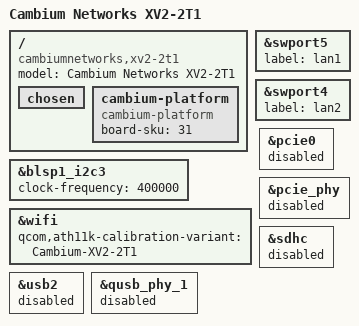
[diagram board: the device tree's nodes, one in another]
// SPDX-License-Identifier: (GPL-2.0+)

/*
 * First, RAM-only XV2-2T1 trial. The existing XE3-4 port supplies the
 * IPQ6018 Ethernet/flash baseline; the 7.2-r1 OEM XV2-2T1 tree supplies
 * the board identity and the corrected SPI-NOR partition layout.
 *
 * No persistent storage, boot environment, or PoE output is enabled for
 * writing/operation by this recovery tree. The integrated radio is enabled
 * only for the physically checked XV2-2T1 variant in the radio trial.
 */

#include "ipq6010-xe3-4.dts"
#include "ipq6010-jaguar-storage-recovery.dtsi"
#include "ipq6010-jaguar-controls.dtsi"

/ {
	model = "Cambium Networks XV2-2T1";
	compatible = "cambiumnetworks,xv2-2t1", "qcom,ipq6018-ap-cp01-c1",
		     "qcom,ipq6018-ap-cp01", "qcom,ipq6018";

	chosen {
		/delete-property/ bootargs-append;
	};

	cambium-platform {
		compatible = "cambium-platform";
		board-sku = <31>;
	};
};

/* The OEM XV2-2T1 uses the same MDIO addresses and switch ports as XE3-4. */
&swport5 {
	label = "lan1";
};

&swport4 {
	label = "lan2";
};

&blsp1_i2c3 {
	clock-frequency = <400000>;
};

/* The XV2-2T1 integrated IPQ6018 radio uses OEM board ID 0x13 data. */
&wifi {
	status = "okay";
	qcom,ath11k-calibration-variant = "Cambium-XV2-2T1";
};

&pcie0 {
	status = "disabled";
};

&pcie_phy {
	status = "disabled";
};

&sdhc {
	status = "disabled";
};

&usb2 {
	status = "disabled";
};

&qusb_phy_1 {
	status = "disabled";
};
